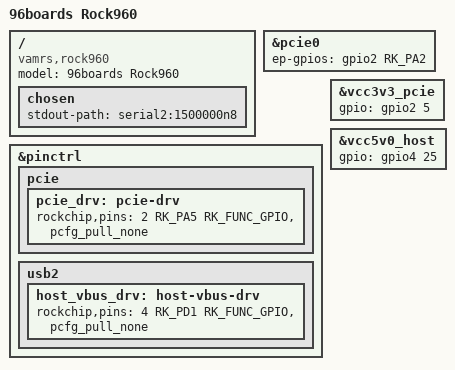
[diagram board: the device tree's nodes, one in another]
// SPDX-License-Identifier: GPL-2.0+
/*
 * Copyright (C) 2018 Manivannan Sadhasivam <manivannan.sadhasivam@linaro.org>
 */

/dts-v1/;
#include "rk3399-rock960.dtsi"

/ {
	model = "96boards Rock960";
	compatible = "vamrs,rock960", "rockchip,rk3399";

	chosen {
		stdout-path = "serial2:1500000n8";
	};
};

&pcie0 {
	ep-gpios = <&gpio2 RK_PA2 GPIO_ACTIVE_HIGH>;
};

&pinctrl {
	pcie {
		pcie_drv: pcie-drv {
			rockchip,pins =
				<2 RK_PA5 RK_FUNC_GPIO &pcfg_pull_none>;
			};
	};

	usb2 {
		host_vbus_drv: host-vbus-drv {
			rockchip,pins =
				<4 RK_PD1 RK_FUNC_GPIO &pcfg_pull_none>;
		};
	};
};

&vcc3v3_pcie {
	gpio = <&gpio2 5 GPIO_ACTIVE_HIGH>;
};

&vcc5v0_host {
	gpio = <&gpio4 25 GPIO_ACTIVE_HIGH>;
};
